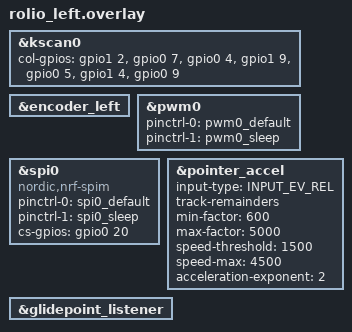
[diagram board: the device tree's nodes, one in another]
#include "rolio.dtsi"
#include <behaviors/input_gestures_accel.dtsi>

&kscan0 {
    col-gpios
        = <&gpio1 2 GPIO_ACTIVE_HIGH>
        , <&gpio0 7 GPIO_ACTIVE_HIGH>
        , <&gpio0 4 GPIO_ACTIVE_HIGH>
        , <&gpio1 9 GPIO_ACTIVE_HIGH>
        , <&gpio0 5 GPIO_ACTIVE_HIGH>
        , <&gpio1 4 GPIO_ACTIVE_HIGH>
        , <&gpio0 9 GPIO_ACTIVE_HIGH>
        ;
};

&encoder_left {
    status = "okay";
};

&pwm0 {
  status = "okay";
  pinctrl-0 = <&pwm0_default>;
  pinctrl-1 = <&pwm0_sleep>;
  pinctrl-names = "default", "sleep";
};

// Enable SPI for MIP display 
nice_view_spi: &spi0 {
    compatible = "nordic,nrf-spim";
    pinctrl-0 = <&spi0_default>;
    pinctrl-1 = <&spi0_sleep>;
    pinctrl-names = "default", "sleep";
    cs-gpios = <&gpio0 20 GPIO_ACTIVE_HIGH>;
};

// Conifgure the pointer acceleration:
//
//     Relevant doc: https://github.com/oleksandrmaslov/zmk-pointing-acceleration
//
&pointer_accel {
    input-type = <INPUT_EV_REL>; // For relative input devices
    track-remainders;            // Accumulate fractional movements
    min-factor = <600>;          // 0.6x at very slow speeds
    max-factor = <5000>;         // 5x at fast speeds
    speed-threshold = <1500>;    // 1200 counts/sec for 1x
    speed-max = <4500>;          // 4500 counts/sec for max accel
    acceleration-exponent = <2>; // Quadratic acceleration curve
};

&glidepoint_listener {
    status = "okay";
};
